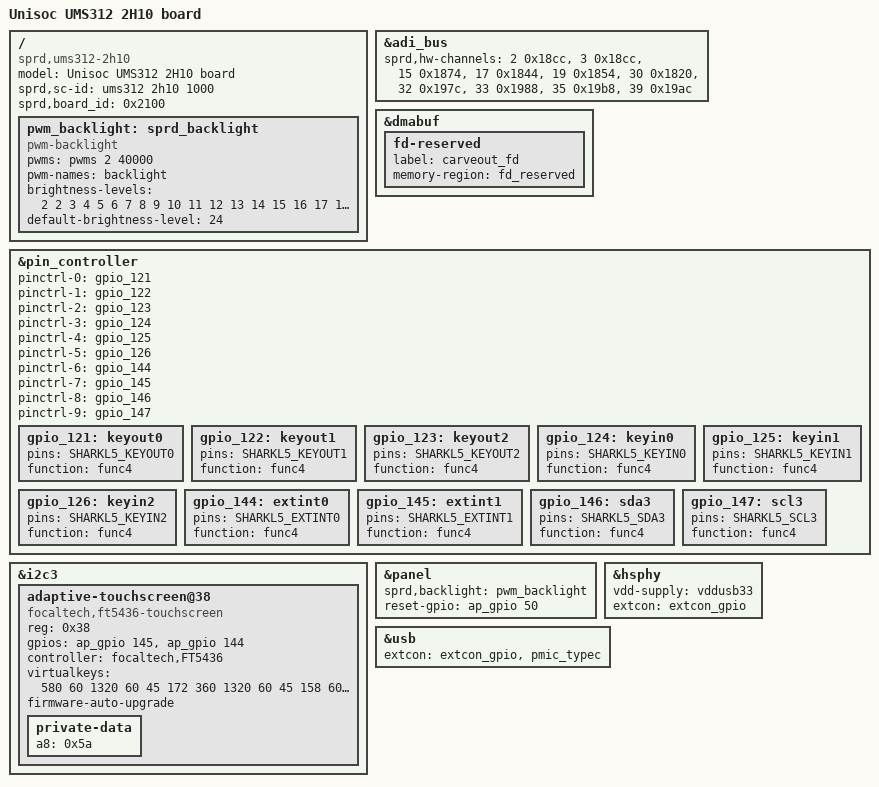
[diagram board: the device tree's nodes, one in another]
// SPDX-License-Identifier: GPL-2.0-only
/*
 * UNISOC UMS312 board common DTS file
 *
 * Copyright (C) 2021, Unisoc Inc.
 */

/dts-v1/;
/plugin/;

#include <dt-bindings/input/input.h>
#include <dt-bindings/gpio/gpio.h>
#include <dt-bindings/clock/sprd,ums312-clk.h>
#include <dt-bindings/mfd/sprd,sc2730-regs.h>
#include <dt-bindings/mfd/sprd,sc2730-mask.h>
#include "lcd/lcd_r61350_truly_mipi_hd.dtsi"
#include "lcd/lcd_ili9881c_truly_mipi_hd.dtsi"
#include "lcd/lcd_dummy_mipi.dtsi"
#include "reserved-memory/ums312-2h10-overlay.dtsi"

/ {
	model = "Unisoc UMS312 2H10 board";

	compatible = "sprd,ums312-2h10";

	sprd,sc-id = "ums312 2h10 1000";

	sprd,board_id = <0x2100>; //XX00:base board,XX00~XXFF:customize board

	fragment {
		target-path = "/";
		__overlay__ {
				pwm_backlight: sprd_backlight {
					compatible = "pwm-backlight";
					pwms = <&pwms 2 40000>;
					pwm-names = "backlight";
					brightness-levels = <
						      2   2   3   4   5   6   7   8   9
						 10  11  12  13  14  15  16  17  18  19
						 20  21  22  23  24  25  26  27  28  29
						 30  31  32  33  34  35  36  37  38  39
						 40  41  42  43  44  45  46  47  48  49
						 50  51  52  53  54  55  56  57  58  59
						 60  61  62  63  64  65  66  67  68  69
						 70  71  72  73  74  75  76  77  78  79
						 80  81  82  83  84  85  86  87  88  89
						 90  91  92  93  94  95  96  97  98  99
						100 101 102 103 104 105 106 107 108 109
						110 111 112 113 114 115 116 117 118 119
						120 121 122 123 124 125 126 127 128 129
						130 131 132 133 134 135 136 137 138 139
						140 141 142 143 144 145 146 147 148 149
						150 151 152 153 154 155 156 157 158 159
						160 161 162 163 164 165 166 167 168 169
						170 171 172 173 174 175 176 177 178 179
						180 181 182 183 184 185 186 187 188 189
						190 191 192 193 194 195 196 197 198 199
						200 201 202 203 204 205 206 207 208 209
						210 211 212 213 214 215 216 217 218 219
						220 221 222 223 224 225 226 227 228 229
						230 231 232 233 234 235 236 237 238 239
						240 241 242 243 244 245 246 247 247 247
						247 247 247 247 247 247 247
						>;
					default-brightness-level = <24>;
				};
			};
		};
};

&adi_bus {
	sprd,hw-channels = <2 0x18cc>, <3 0x18cc>, <15 0x1874>,
			   <17 0x1844>, <19 0x1854>, <30 0x1820>,
			   <32 0x197c>, <33 0x1988>, <35 0x19b8>, <39 0x19ac>;
};

&dmabuf {

	fd-reserved {
		label = "carveout_fd";
		memory-region = <&fd_reserved>;
	};

};

&pin_controller {
	pinctrl-names =
	/* keyout0 ~ keyout2 */
	"gpio_121", "gpio_122", "gpio_123",
	/* keyin0 ~ keyin2 */
	"gpio_124", "gpio_125", "gpio_126",
	/* extint0, extint1, sda3, scl3 */
	"gpio_144", "gpio_145", "gpio_146", "gpio_147";
	pinctrl-0 = <&gpio_121>;
	pinctrl-1 = <&gpio_122>;
	pinctrl-2 = <&gpio_123>;
	pinctrl-3 = <&gpio_124>;
	pinctrl-4 = <&gpio_125>;
	pinctrl-5 = <&gpio_126>;
	pinctrl-6 = <&gpio_144>;
	pinctrl-7 = <&gpio_145>;
	pinctrl-8 = <&gpio_146>;
	pinctrl-9 = <&gpio_147>;

	gpio_121: keyout0 {
		pins = "SHARKL5_KEYOUT0";
		function = "func4";
	};

	gpio_122: keyout1 {
		pins = "SHARKL5_KEYOUT1";
		function = "func4";
	};

	gpio_123: keyout2 {
		pins = "SHARKL5_KEYOUT2";
		function = "func4";
	};

	gpio_124: keyin0 {
		pins = "SHARKL5_KEYIN0";
		function = "func4";
	};

	gpio_125: keyin1 {
		pins = "SHARKL5_KEYIN1";
		function = "func4";
	};

	gpio_126: keyin2 {
		pins = "SHARKL5_KEYIN2";
		function = "func4";
	};

	gpio_144: extint0 {
		pins = "SHARKL5_EXTINT0";
		function = "func4";
	};

	gpio_145: extint1 {
		pins = "SHARKL5_EXTINT1";
		function = "func4";
	};

	gpio_146: sda3 {
		pins = "SHARKL5_SDA3";
		function = "func4";
	};

	gpio_147: scl3 {
		pins = "SHARKL5_SCL3";
		function = "func4";
	};
};

&i2c3 {
	status = "okay";
	#address-cells = <1>;
	#size-cells = <0>;

	adaptive-touchscreen@38 {
		compatible = "focaltech,ft5436-touchscreen";
		reg = <0x38>;
		gpios = <&ap_gpio 145 GPIO_ACTIVE_HIGH
			 &ap_gpio 144 GPIO_ACTIVE_HIGH>;
		controller = "focaltech,FT5436";
		virtualkeys = <580 60 1320 60 45
				172 360 1320 60 45
				158 600 1320 60 45>;
		firmware-auto-upgrade;
		private-data {
			a8 = /bits/ 8 <0x5a>;
		};
	};
};

&panel {
	sprd,backlight = <&pwm_backlight>;
	reset-gpio = <&ap_gpio 50 GPIO_ACTIVE_HIGH>;
};

&hsphy {
	vdd-supply = <&vddusb33>;
	extcon = <&extcon_gpio>;
};

&usb {
	extcon = <&extcon_gpio>, <&pmic_typec>;
//	vbus-supply = <&vddvbus>;
};
